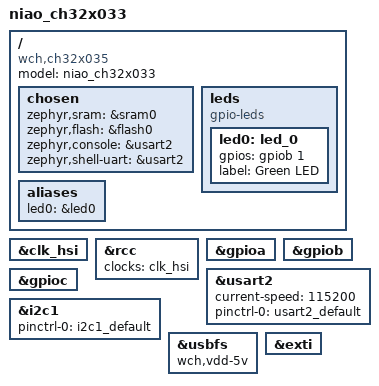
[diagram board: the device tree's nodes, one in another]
/*
 * Copyright (c) 2026 carrefinho
 *
 * SPDX-License-Identifier: MIT
 */

/dts-v1/;

#include <wch/ch32x0/ch32x033f8p6.dtsi>
#include <zephyr/dt-bindings/gpio/gpio.h>
#include "niao_ch32x033-pinctrl.dtsi"
#include "seeed_xiao_connector.dtsi"

/ {
	model = "niao_ch32x033";
	compatible = "wch,ch32x035";

	chosen {
		zephyr,sram = &sram0;
		zephyr,flash = &flash0;
		zephyr,console = &usart2;
		zephyr,shell-uart = &usart2;
	};

	leds {
		compatible = "gpio-leds";

		led0: led_0 {
			/* PB1 -> 2k2 -> green LED -> GND, so active high. */
			gpios = <&gpiob 1 GPIO_ACTIVE_HIGH>;
			label = "Green LED";
		};
	};

	aliases {
		led0 = &led0;
	};
};

&clk_hsi {
	status = "okay";
};

&rcc {
	clocks = <&clk_hsi>;
};

&gpioa {
	status = "okay";
};

&gpiob {
	status = "okay";
};

&gpioc {
	status = "okay";
};

&usart2 {
	status = "okay";
	current-speed = <115200>;
	pinctrl-0 = <&usart2_default>;
	pinctrl-names = "default";
};

&i2c1 {
	pinctrl-0 = <&i2c1_default>;
	pinctrl-names = "default";
};

/*
 * USB-C, bus powered. VDD is tied straight to the 5V rail (there is no 3V3
 * regulator on the board and the XIAO 3V3 pad is unconnected), so the PHY
 * runs in 5V mode: internal LDO off, 10K D+ pull-up.
 */
&usbfs {
	status = "okay";
	wch,vdd-5v;
};

zephyr_udc0: &usbfs {};

&exti {
	status = "okay";
};
